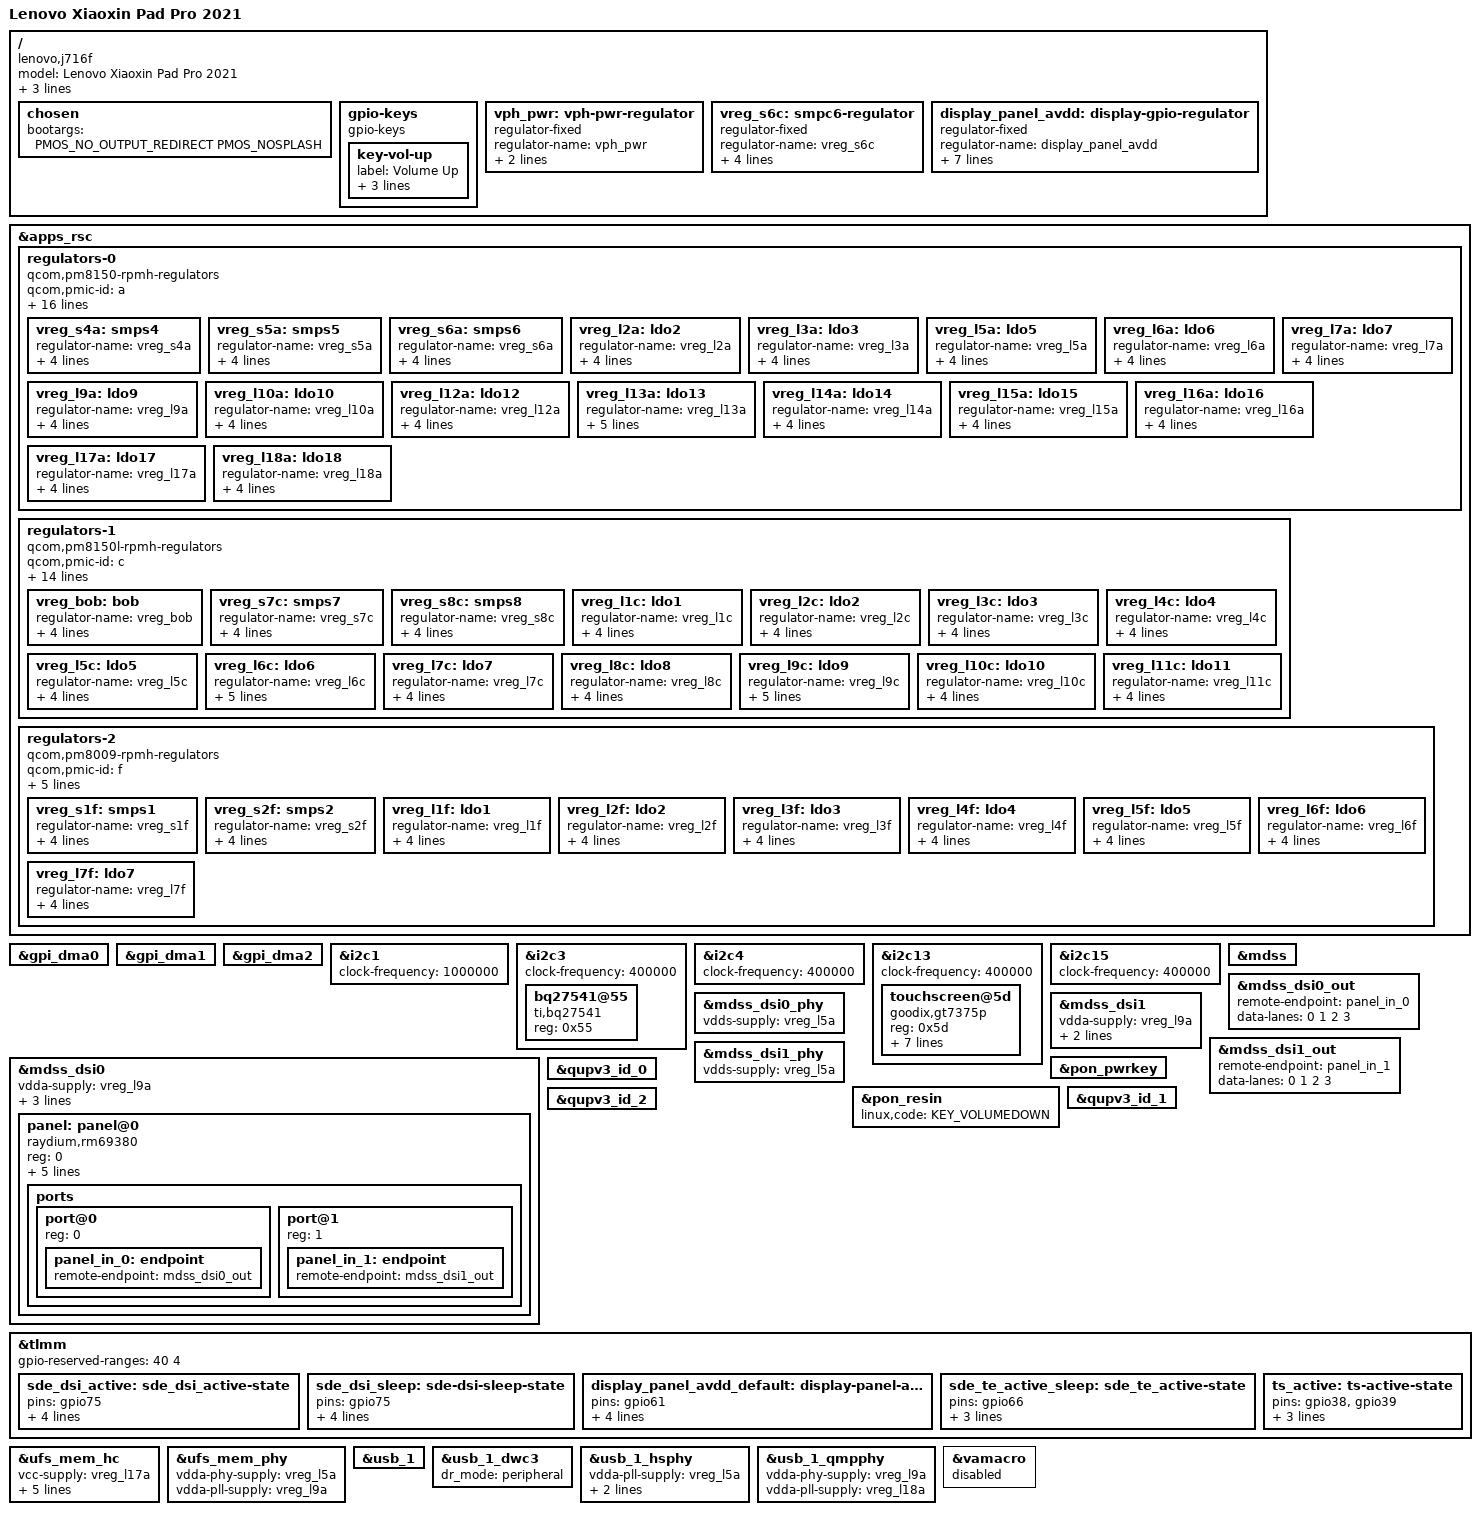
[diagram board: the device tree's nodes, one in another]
// SPDX-License-Identifier: GPL-2.0
/*
 * Copyright (c) 2024, David Wronek <david@mainlining.org>
 */

/dts-v1/;

#include <dt-bindings/arm/qcom,ids.h>
#include <dt-bindings/gpio/gpio.h>
#include <dt-bindings/regulator/qcom,rpmh-regulator.h>
#include "sm8250.dtsi"
#include "pm8150.dtsi"
#include "pm8150b.dtsi"
#include "pm8150l.dtsi"
#include "pm8009.dtsi"

/ {
	model = "Lenovo Xiaoxin Pad Pro 2021";
	compatible = "lenovo,j716f", "qcom,sm8250";
	chassis-type = "tablet";

	qcom,msm-id = <QCOM_ID_SM8250 0x20001>;
	qcom,board-id = <0x2010008 0>;

	chosen {
		bootargs = "PMOS_NO_OUTPUT_REDIRECT PMOS_NOSPLASH";
	};

	gpio-keys {
		compatible = "gpio-keys";

		key-vol-up {
			label = "Volume Up";
			linux,code = <KEY_VOLUMEUP>;
			gpios = <&pm8150_gpios 6 GPIO_ACTIVE_LOW>;
			debounce-interval = <15>;
		};
	};

	vph_pwr: vph-pwr-regulator {
		compatible = "regulator-fixed";
		regulator-name = "vph_pwr";
		regulator-min-microvolt = <3700000>;
		regulator-max-microvolt = <3700000>;
	};

	/* S6c is really ebi.lvl but it's there for supply map completeness sake. */
	vreg_s6c: smpc6-regulator {
		compatible = "regulator-fixed";
		regulator-name = "vreg_s6c";

		regulator-min-microvolt = <880000>;
		regulator-max-microvolt = <880000>;
		regulator-always-on;
		vin-supply = <&vph_pwr>;
	};

	display_panel_avdd: display-gpio-regulator {
		compatible = "regulator-fixed";
		regulator-name = "display_panel_avdd";
		regulator-min-microvolt = "5500000";
		regulator-max-microvolt = "5500000";
		regulator-enable-ramp-delay = <233>;

		pinctrl-0 = <&display_panel_avdd_default>;
		pinctrl-names = "default";

		gpio = <&tlmm 61 GPIO_ACTIVE_HIGH>;
		enable-active-high;
		regulator-boot-on;
	};
};

&apps_rsc {
	regulators-0 {
		compatible = "qcom,pm8150-rpmh-regulators";
		qcom,pmic-id = "a";

		vdd-s1-supply = <&vph_pwr>;
		vdd-s2-supply = <&vph_pwr>;
		vdd-s3-supply = <&vph_pwr>;
		vdd-s4-supply = <&vph_pwr>;
		vdd-s5-supply = <&vph_pwr>;
		vdd-s6-supply = <&vph_pwr>;
		vdd-s7-supply = <&vph_pwr>;
		vdd-s8-supply = <&vph_pwr>;
		vdd-s9-supply = <&vph_pwr>;
		vdd-s10-supply = <&vph_pwr>;
		vdd-l1-l8-l11-supply = <&vreg_s6c>;
		vdd-l2-l10-supply = <&vreg_bob>;
		vdd-l3-l4-l5-l18-supply = <&vreg_s6a>;
		vdd-l6-l9-supply = <&vreg_s8c>;
		vdd-l7-l12-l14-l15-supply = <&vreg_s5a>;
		vdd-l13-l16-l17-supply = <&vreg_bob>;

		/* (S1+S2+S3) - cx.lvl (ARC) */

		vreg_s4a: smps4 {
			regulator-name = "vreg_s4a";
			regulator-min-microvolt = <1800000>;
			regulator-max-microvolt = <1920000>;
			regulator-initial-mode = <RPMH_REGULATOR_MODE_HPM>;
		};

		vreg_s5a: smps5 {
			regulator-name = "vreg_s5a";
			regulator-min-microvolt = <1900000>;
			regulator-max-microvolt = <2040000>;
			regulator-initial-mode = <RPMH_REGULATOR_MODE_HPM>;
		};

		vreg_s6a: smps6 {
			regulator-name = "vreg_s6a";
			regulator-min-microvolt = <950000>;
			regulator-max-microvolt = <1128000>;
			regulator-initial-mode = <RPMH_REGULATOR_MODE_HPM>;
		};

		vreg_l2a: ldo2 {
			regulator-name = "vreg_l2a";
			regulator-min-microvolt = <3072000>;
			regulator-max-microvolt = <3072000>;
			regulator-initial-mode = <RPMH_REGULATOR_MODE_HPM>;
		};

		vreg_l3a: ldo3 {
			regulator-name = "vreg_l3a";
			regulator-min-microvolt = <928000>;
			regulator-max-microvolt = <932000>;
			regulator-initial-mode = <RPMH_REGULATOR_MODE_HPM>;
		};

		/* L4 - lmx.lvl (ARC) */

		vreg_l5a: ldo5 {
			regulator-name = "vreg_l5a";
			regulator-min-microvolt = <880000>;
			regulator-max-microvolt = <880000>;
			regulator-initial-mode = <RPMH_REGULATOR_MODE_HPM>;
		};

		vreg_l6a: ldo6 {
			regulator-name = "vreg_l6a";
			regulator-min-microvolt = <1200000>;
			regulator-max-microvolt = <1200000>;
			regulator-initial-mode = <RPMH_REGULATOR_MODE_HPM>;
		};

		vreg_l7a: ldo7 {
			regulator-name = "vreg_l7a";
			regulator-min-microvolt = <1704000>;
			regulator-max-microvolt = <1800000>;
			regulator-initial-mode = <RPMH_REGULATOR_MODE_HPM>;
		};

		vreg_l9a: ldo9 {
			regulator-name = "vreg_l9a";
			regulator-min-microvolt = <1200000>;
			regulator-max-microvolt = <1200000>;
			regulator-initial-mode = <RPMH_REGULATOR_MODE_HPM>;
		};

		vreg_l10a: ldo10 {
			regulator-name = "vreg_l10a";
			regulator-min-microvolt = <1800000>;
			regulator-max-microvolt = <2960000>;
			regulator-initial-mode = <RPMH_REGULATOR_MODE_HPM>;
		};

		/* L11 - lcx.lvl (ARC) */

		vreg_l12a: ldo12 {
			regulator-name = "vreg_l12a";
			regulator-min-microvolt = <1800000>;
			regulator-max-microvolt = <1800000>;
			regulator-initial-mode = <RPMH_REGULATOR_MODE_HPM>;
		};

		vreg_l13a: ldo13 {
			regulator-name = "vreg_l13a";
			regulator-min-microvolt = <3008000>;
			regulator-max-microvolt = <3008000>;
			regulator-initial-mode = <RPMH_REGULATOR_MODE_HPM>;

			regualtor-always-on; //TEMP
		};

		vreg_l14a: ldo14 {
			regulator-name = "vreg_l14a";
			regulator-min-microvolt = <1800000>;
			regulator-max-microvolt = <1880000>;
			regulator-initial-mode = <RPMH_REGULATOR_MODE_HPM>;
		};

		vreg_l15a: ldo15 {
			regulator-name = "vreg_l15a";
			regulator-min-microvolt = <1800000>;
			regulator-max-microvolt = <1800000>;
			regulator-initial-mode = <RPMH_REGULATOR_MODE_HPM>;
		};

		vreg_l16a: ldo16 {
			regulator-name = "vreg_l16a";
			regulator-min-microvolt = <3024000>;
			regulator-max-microvolt = <3304000>;
			regulator-initial-mode = <RPMH_REGULATOR_MODE_HPM>;
		};

		vreg_l17a: ldo17 {
			regulator-name = "vreg_l17a";
			regulator-min-microvolt = <2496000>;
			regulator-max-microvolt = <3008000>;
			regulator-initial-mode = <RPMH_REGULATOR_MODE_HPM>;
		};

		vreg_l18a: ldo18 {
			regulator-name = "vreg_l18a";
			regulator-min-microvolt = <800000>;
			regulator-max-microvolt = <920000>;
			regulator-initial-mode = <RPMH_REGULATOR_MODE_HPM>;
		};
	};

	/*
	 * Remaining regulators that are not yet supported:
	 * OLEDB: 4925000-8100000
	 * ab: 4600000-6100000
	 * ibb: 800000-5400000
	 */

	regulators-1 {
		compatible = "qcom,pm8150l-rpmh-regulators";
		qcom,pmic-id = "c";

		vdd-s1-supply = <&vph_pwr>;
		vdd-s2-supply = <&vph_pwr>;
		vdd-s3-supply = <&vph_pwr>;
		vdd-s4-supply = <&vph_pwr>;
		vdd-s5-supply = <&vph_pwr>;
		vdd-s6-supply = <&vph_pwr>;
		vdd-s7-supply = <&vph_pwr>;
		vdd-s8-supply = <&vph_pwr>;
		vdd-l1-l8-supply = <&vreg_s4a>;
		vdd-l2-l3-supply = <&vreg_s8c>;
		vdd-l4-l5-l6-supply = <&vreg_bob>;
		vdd-l7-l11-supply = <&vreg_bob>;
		vdd-l9-l10-supply = <&vreg_bob>;
		vdd-bob-supply = <&vph_pwr>;

		vreg_bob: bob {
			regulator-name = "vreg_bob";
			regulator-min-microvolt = <3008000>;
			regulator-max-microvolt = <3960000>;
			regulator-initial-mode = <RPMH_REGULATOR_MODE_AUTO>;
		};

		/*
		 * S1-S6 are ARCs:
		 * (S1+S2) - gfx.lvl,
		 * S3 - mx.lvl,
		 * (S4+S5) - mmcx.lvl,
		 * S6 - ebi.lvl
		 */

		vreg_s7c: smps7 {
			regulator-name = "vreg_s7c";
			regulator-min-microvolt = <348000>;
			regulator-max-microvolt = <1000000>;
			regulator-initial-mode = <RPMH_REGULATOR_MODE_HPM>;
		};

		vreg_s8c: smps8 {
			regulator-name = "vreg_s8c";
			regulator-min-microvolt = <1350000>;
			regulator-max-microvolt = <1400000>;
			regulator-initial-mode = <RPMH_REGULATOR_MODE_HPM>;
		};

		vreg_l1c: ldo1 {
			regulator-name = "vreg_l1c";
			regulator-min-microvolt = <1800000>;
			regulator-max-microvolt = <1800000>;
			regulator-initial-mode = <RPMH_REGULATOR_MODE_HPM>;
		};

		vreg_l2c: ldo2 {
			regulator-name = "vreg_l2c";
			regulator-min-microvolt = <1200000>;
			regulator-max-microvolt = <1304000>;
			regulator-initial-mode = <RPMH_REGULATOR_MODE_HPM>;
		};

		vreg_l3c: ldo3 {
			regulator-name = "vreg_l3c";
			regulator-min-microvolt = <800000>;
			regulator-max-microvolt = <1200000>;
			regulator-initial-mode = <RPMH_REGULATOR_MODE_HPM>;
		};

		vreg_l4c: ldo4 {
			regulator-name = "vreg_l4c";
			regulator-min-microvolt = <1800000>;
			regulator-max-microvolt = <2800000>;
			regulator-initial-mode = <RPMH_REGULATOR_MODE_HPM>;
		};

		vreg_l5c: ldo5 {
			regulator-name = "vreg_l5c";
			regulator-min-microvolt = <1800000>;
			regulator-max-microvolt = <2800000>;
			regulator-initial-mode = <RPMH_REGULATOR_MODE_HPM>;
		};

		vreg_l6c: ldo6 {
			regulator-name = "vreg_l6c";
			regulator-min-microvolt = <1800000>;
			regulator-max-microvolt = <2960000>;
			regulator-initial-mode = <RPMH_REGULATOR_MODE_HPM>;
			regulator-allow-set-load;
		};

		vreg_l7c: ldo7 {
			regulator-name = "vreg_l7c";
			regulator-min-microvolt = <2856000>;
			regulator-max-microvolt = <3104000>;
			regulator-initial-mode = <RPMH_REGULATOR_MODE_HPM>;
		};

		vreg_l8c: ldo8 {
			regulator-name = "vreg_l8c";
			regulator-min-microvolt = <1800000>;
			regulator-max-microvolt = <1800000>;
			regulator-initial-mode = <RPMH_REGULATOR_MODE_HPM>;
		};

		vreg_l9c: ldo9 {
			regulator-name = "vreg_l9c";
			regulator-min-microvolt = <2704000>;
			regulator-max-microvolt = <2960000>;
			regulator-initial-mode = <RPMH_REGULATOR_MODE_HPM>;
			regulator-allow-set-load;
		};

		vreg_l10c: ldo10 {
			regulator-name = "vreg_l10c";
			regulator-min-microvolt = <3000000>;
			regulator-max-microvolt = <3312000>;
			regulator-initial-mode = <RPMH_REGULATOR_MODE_HPM>;
		};

		vreg_l11c: ldo11 {
			regulator-name = "vreg_l11c";
			regulator-min-microvolt = <3104000>;
			regulator-max-microvolt = <3304000>;
			regulator-initial-mode = <RPMH_REGULATOR_MODE_HPM>;
		};
	};

	regulators-2 {
		compatible = "qcom,pm8009-rpmh-regulators";
		qcom,pmic-id = "f";

		vdd-s1-supply = <&vph_pwr>;
		vdd-s2-supply = <&vreg_bob>;
		vdd-l2-supply = <&vreg_s8c>;
		vdd-l5-l6-supply = <&vreg_bob>;
		vdd-l7-supply = <&vreg_s4a>;

		vreg_s1f: smps1 {
			regulator-name = "vreg_s1f";
			regulator-min-microvolt = <1200000>;
			regulator-max-microvolt = <1200000>;
			regulator-initial-mode = <RPMH_REGULATOR_MODE_HPM>;
		};

		vreg_s2f: smps2 {
			regulator-name = "vreg_s2f";
			regulator-min-microvolt = <512000>;
			regulator-max-microvolt = <1100000>;
			regulator-initial-mode = <RPMH_REGULATOR_MODE_HPM>;
		};

		vreg_l1f: ldo1 {
			regulator-name = "vreg_l1f";
			regulator-min-microvolt = <1104000>;
			regulator-max-microvolt = <1200000>;
			regulator-initial-mode = <RPMH_REGULATOR_MODE_HPM>;
		};

		vreg_l2f: ldo2 {
			regulator-name = "vreg_l2f";
			regulator-min-microvolt = <1200000>;
			regulator-max-microvolt = <1200000>;
			regulator-initial-mode = <RPMH_REGULATOR_MODE_HPM>;
		};

		vreg_l3f: ldo3 {
			regulator-name = "vreg_l3f";
			regulator-min-microvolt = <1056000>;
			regulator-max-microvolt = <1200000>;
			regulator-initial-mode = <RPMH_REGULATOR_MODE_HPM>;
		};

		vreg_l4f: ldo4 {
			regulator-name = "vreg_l4f";
			regulator-min-microvolt = <1096000>;
			regulator-max-microvolt = <1304000>;
			regulator-initial-mode = <RPMH_REGULATOR_MODE_HPM>;
		};

		vreg_l5f: ldo5 {
			regulator-name = "vreg_l5f";
			regulator-min-microvolt = <2800000>;
			regulator-max-microvolt = <3000000>;
			regulator-initial-mode = <RPMH_REGULATOR_MODE_HPM>;
		};

		vreg_l6f: ldo6 {
			regulator-name = "vreg_l6f";
			regulator-min-microvolt = <2800000>;
			regulator-max-microvolt = <3000000>;
			regulator-initial-mode = <RPMH_REGULATOR_MODE_HPM>;
		};

		vreg_l7f: ldo7 {
			regulator-name = "vreg_l7f";
			regulator-min-microvolt = <1800000>;
			regulator-max-microvolt = <1800000>;
			regulator-initial-mode = <RPMH_REGULATOR_MODE_HPM>;
		};
	};
};

&gpi_dma0 {
	status = "okay";
};

&gpi_dma1 {
	status = "okay";
};

&gpi_dma2 {
	status = "okay";
};

&i2c1 {
	clock-frequency = <1000000>;
	status = "okay";

	/* hid-over-i2c ptp @ 60 */
};

&i2c3 {
	clock-frequency = <400000>;
	status = "okay";

	bq27541@55 {
		compatible = "ti,bq27541";
		reg = <0x55>;
	};
};

&i2c4 {
	clock-frequency = <400000>;
	status = "okay";

	/* onsemi NB7VPQ904M (USB Redriver) @ 19 */
	/* Cirrus CS35L41 (Speaker 1) @ 40 */
	/* Cirrus CS35L41 (Speaker 2) @ 41 */
	/* Cirrus CS35L41 (Speaker 3) @ 42 */
	/* Cirrus CS35L41 (Speaker 4) @ 43 */
	/* hid-over-i2c keyboard @ 61 */
};

&i2c13 {
	clock-frequency = <400000>;
	status = "okay";

	/* Touchscreen is actually GT7385P */
	touchscreen@5d {
		compatible = "goodix,gt7375p";
		reg = <0x5d>;
		pinctrl-names = "default";
		pinctrl-0 = <&ts_active>;

		interrupt-parent = <&tlmm>;
		interrupts = <39 IRQ_TYPE_EDGE_BOTH>;

		panel = <&panel>;
		reset-gpios = <&tlmm 38 GPIO_ACTIVE_HIGH>;

		vdd-supply = <&vreg_l1c>;
		mainboard-vddio-supply = <&vreg_l14a>;
	};
};

&i2c15 {
	clock-frequency = <400000>;
	status = "okay";

	/* Qcom SMB1390 @ 10 */
	/* HALO HL6111R Qi charger @ 25 */
	/* Everest-semi ES7210 4-ch ADC @ 40 */
	/* onsemi FSA4480 USB-C audio switch @ 43 */
	/* Richwave RTC6226 FM Radio Receiver @ 64 */
};

&mdss {
	status = "okay";
};

&mdss_dsi0 {
	vdda-supply = <&vreg_l9a>;
	qcom,dual-dsi-mode;
	qcom,sync-dual-dsi;
	qcom,master-dsi;

	status = "okay";

	panel: panel@0 {
		compatible = "raydium,rm69380";
		reg = <0>;

		vddio-supply = <&vreg_l14a>;
		avdd-supply = <&display_panel_avdd>;
		reset-gpios = <&tlmm 75 GPIO_ACTIVE_LOW>;

		pinctrl-0 = <&sde_dsi_active &sde_te_active_sleep>;
		pinctrl-1 = <&sde_dsi_sleep &sde_te_active_sleep>;
		pinctrl-names = "default", "sleep";

		#address-cells = <1>;
		#size-cells = <0>;

		ports {
			#address-cells = <1>;
			#size-cells = <0>;

			port@0 {
				reg = <0>;

				panel_in_0: endpoint {
					remote-endpoint = <&mdss_dsi0_out>;
				};
			};

			port@1 {
				reg = <1>;

				panel_in_1: endpoint {
					remote-endpoint = <&mdss_dsi1_out>;
				};
			};
		};
	};
};

&mdss_dsi0_out {
	remote-endpoint = <&panel_in_0>;
	data-lanes = <0 1 2 3>;
};

&mdss_dsi0_phy {
	vdds-supply = <&vreg_l5a>;
	status = "okay";
};

&mdss_dsi1 {
	vdda-supply = <&vreg_l9a>;
	qcom,dual-dsi-mode;
	qcom,sync-dual-dsi;
	/* DSI1 is slave, so use DSI0 clocks */
	//assigned-clock-parents = <&mdss_dsi0_phy 0>, <&mdss_dsi0_phy 1>;
	status = "okay";
};

&mdss_dsi1_out {
	remote-endpoint = <&panel_in_1>;
	data-lanes = <0 1 2 3>;
};

&mdss_dsi1_phy {
	vdds-supply = <&vreg_l5a>;
	status = "okay";
};

&pon_pwrkey {
	status = "okay";
};

&pon_resin {
	linux,code = <KEY_VOLUMEDOWN>;
	status = "okay";
};

&qupv3_id_0 {
	status = "okay";
};

&qupv3_id_1 {
	status = "okay";
};

&qupv3_id_2 {
	status = "okay";
};

//&slpi {
//	firmware-name = "qcom/sm8250/LENOVO/J716F/slpi.mbn";
//	status = "okay";
//};

&tlmm {
	gpio-reserved-ranges = <40 4>;

	sde_dsi_active: sde_dsi_active-state {
		pins = "gpio75";
		function = "gpio";
		drive-strength = <8>;
		bias-disable;
		output-high;
	};

	sde_dsi_sleep: sde-dsi-sleep-state {
		pins = "gpio75";
		function = "gpio";
		drive-strength = <2>;
		bias-pull-down;
		output-high;
	};

	display_panel_avdd_default: display-panel-avdd-default-state {
		pins = "gpio61";
		function = "gpio";
		drive-strength = <8>;
		bias-disable;
		output-high;
	};

	sde_te_active_sleep: sde_te_active-state {
		pins = "gpio66";
		function = "mdp_vsync";
		drive-strength = <2>;
		bias-pull-down;
	};

	ts_active: ts-active-state {
		pins = "gpio38", "gpio39";
		function = "gpio";
		bias-pull-up;
		drive-strength = <8>;
	};
};

&ufs_mem_hc {
	vcc-supply = <&vreg_l17a>;
	vcc-max-microamp = <800000>;
	vccq-supply = <&vreg_l6a>;
	vccq-max-microamp = <800000>;
	vccq2-supply = <&vreg_s4a>;
	vccq2-max-microamp = <800000>;

	status = "okay";
};

&ufs_mem_phy {
	vdda-phy-supply = <&vreg_l5a>;
	vdda-pll-supply = <&vreg_l9a>;

	status = "okay";
};

&usb_1 {
	status = "okay";
};

&usb_1_dwc3 {
	dr_mode = "peripheral";
};

&usb_1_hsphy {
	vdda-pll-supply = <&vreg_l5a>;
	vdda18-supply = <&vreg_l12a>;
	vdda33-supply = <&vreg_l2a>;

	status = "okay";
};

&usb_1_qmpphy {
	vdda-phy-supply = <&vreg_l9a>;
	vdda-pll-supply = <&vreg_l18a>;

	status = "okay";
};

&vamacro {
	status = "disabled";
};
